# ballast register map
Vendor: tuni.fi; File version: 1.0
CPU: other r1p0, little endian, MPU, no FPU, vendor SysTick, 3 interrupt priority bits
Registers are 32-bit, read-only, no defined reset value unless marked. A register's access mark holds for its fields unless they carry their own. Offsets are from the block's base; [hi:lo] are bit positions; lines under a group give offsets from that group; {n}, {i} and the like mark numbered series; 'fields as' and 'values as' point back to an identical list.

## SYSCTRL
Base 0x20000000
0x101000 GPIO group
  0x00 PADDIR rw — Control the direction of each of the GPIO pads. A value of 1 means it is configured as an output, while 0 configures it as an input.
  0x04 PADIN rw — Input Values
  0x08 PADOUT rw — Output values.
  0x0C INTEN rw — Interrupt enable per input bit. INTTYPE0 and INTTYPE1 control the interrupt triggering behavior. There are four triggers available - INTTYPE0 = 0, INTTYPE1 = 0: Level 1 - INTTYPE0 = 1, INTTYPE1 = 0: Level 0 - INTTYPE0 = 0, INTTYPE1 = 1: Rise - INTTYPE0 = 1, INTTYPE1 = 1: Fall
  0x10 INTTYPE0 rw — Interrupt Type 0. Controls the interrupt trigger behavior together with INTTYPE1. Use INTEN to enable interrupts first.
  0x14 INTTYPE1 rw — Controls the interrupt trigger behavior together with INTTYPE0. Use INTEN to enable interrupts first.
  0x18 INTSTATUS rw — Contains interrupt status per GPIO line. The status register is cleared when read. Similarly the interrupt line is high while a bit is set in interrupt status and will be deasserted when the status register is read.
  0x1C GPIOEN rw — Contains the enable bit per GPIO line.
  {0x20+4j} PADCFG{j} rw (j=0..7) — The pad configuration registers control various aspects of the pads that are typically used in ASICs, e.g. drive strength, Schmitt-Triggers, Slew Rate, etc. Since those configuration parameters depend on the exact pads used, each implementation is free to use the PADCFG0-7 registers in every way it wants and also leave them unconnected, if unneeded. 13 Writing to the PADOUTSET address (0x1A10_1040), the content of the PADOUT register is updated with its content "ored" with the write data. Writing to the PADOUTCLR address (0x1A10_1044), the content of the PADOUT register is updated with its content "anded" with the inverted write data.
0x102000 UDMA group
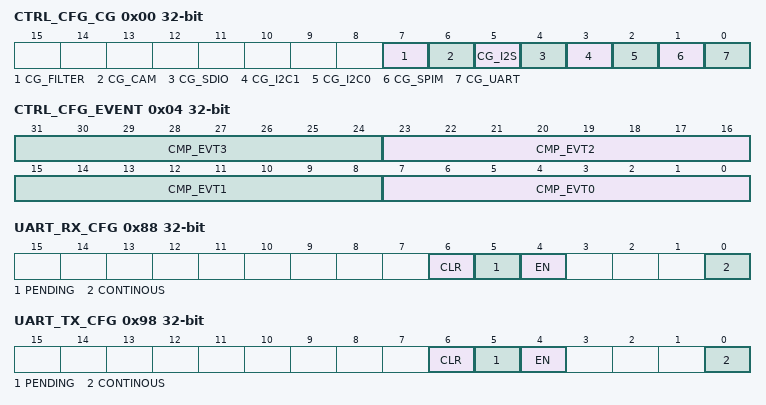
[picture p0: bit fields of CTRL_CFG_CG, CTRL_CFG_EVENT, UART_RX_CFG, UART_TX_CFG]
  0x00 CTRL_CFG_CG rw — uDMA peripherals clock gate configuration Bitfields Defines uDMA peripherals clock gate configuration for corresponding peripheral
    [7] CG_FILTER, [6] CG_CAM, [5] CG_I2S, [4] CG_SDIO, [3] CG_I2C1, [2] CG_I2C0, [1] CG_SPIM, [0] CG_UART
  0x04 CTRL_CFG_EVENT rw — uDMA peripherals external event configuration
    [8n+7:8n] CMP_EVT{n} (n=0..3) — Forward event with ID matching CMP_EVT{n} to peripherals as event{n}
  0x08 CTRL_CFG_RST rw — uDMA peripherals reset trigger (unimplemented)
  0x80 UART_RX_SADDR rw — uDMA RX UART buffer base address configuration register
    [15:0] RX_SADDR — RX buffer base address bitfield: - Read: returns value of the buffer pointer until transfer is finished. Else returns 0. - Write: sets RX buffer base address
  0x84 UART_RX_SIZE rw — uDMA RX UART buffer size configuration register
    [16:0] RX_SIZE — RX buffer size bitfield in bytes. (128kBytes maximum) - Read: returns remaining buffer size to transfer. - Write: sets buffer size.
  0x88 UART_RX_CFG rw — uDMA RX UART stream configuration register
    [6] CLR wo — RX channel clear and stop transfer: -1'b0: disable -1'b1: stop and clear the on-going transfer
    [5] PENDING ro
    [4] EN — RX channel enable and start transfer bitfield: -1'b0: disable -1'b1: enable and start the transfer This signal is used also to queue a transfer if one is already ongoing.
    [0] CONTINOUS — RX channel continuous mode bitfield: -1'b0: disabled -1'b1: enabled At the end of the buffer transfer, the uDMA reloads the address / buffer size and starts a new transfer.
  0x90 UART_TX_SADDR rw — uDMA TX UART buffer base address configuration register.
    [15:0] TX_SADDR — TX buffer base address bitfield: - Read: returns value of the buffer pointer until transfer is finished. Else returns 0. - Write: sets buffer base address
  0x94 UART_TX_SIZE rw — uDMA TX UART buffer size configuration register
    [16:0] TX_SIZE — TX buffer size bitfield in bytes. (128kBytes maximum) - Read: returns remaining buffer size to transfer. - Write: sets buffer size.
  0x98 UART_TX_CFG rw — uDMA TX UART stream configuration register.
    [6] CLR wo — RX channel clear and stop transfer: -1'b0: disable -1'b1: stop and clear the on-going transfer
    [5] PENDING ro — TX transfer pending in queue status flag: -1'b0: no pending transfer in the queue -1'b1: pending transfer in the queue
    [4] EN — TX channel enable and start transfer bitfield: -1'b0: disabled -1'b1: enable and start the transfer This signal is used also to queue a transfer if one is already ongoing.
    [0] CONTINOUS — TX channel continuous mode bitfield: -1'b0: disabled -1'b1: enabled At the end of the buffer transfer, the uDMA reloads the address / buffer size and starts a new transfer.
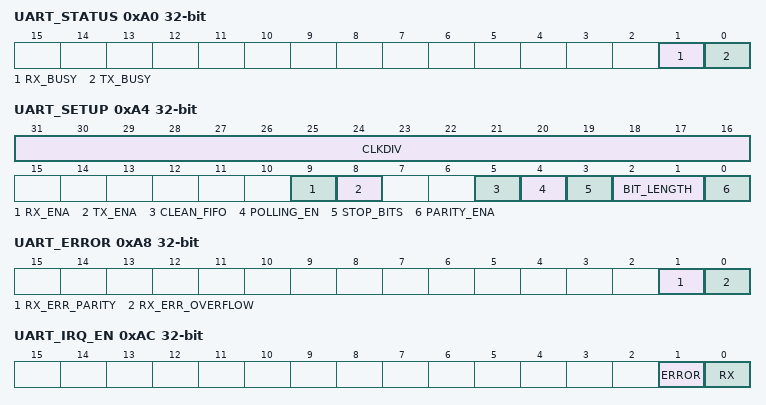
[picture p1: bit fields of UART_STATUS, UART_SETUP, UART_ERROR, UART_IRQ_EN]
  0xA0 UART_STATUS — uDMA UART status register
    [1] RX_BUSY — RX busy status flag: - 1'b0: no RX transfer on-going - 1'b1: RX transfer on-going
    [0] TX_BUSY — TX busy status flag: - 1'b0: no TX transfer on-going - 1'b1: TX transfer on-going
  0xA4 UART_SETUP rw — UDMA UART configuration register.
    [31:16] CLKDIV — UART Clock divider configuration bitfield. The baudrate is equal to SOC_FREQ/CLKDIV.
    [9] RX_ENA — RX transceiver configuration bitfield: - 1'b0: disabled - 1'b1: enabled
    [8] TX_ENA — TX transceiver configuration bitfield: - 1'b0: disabled - 1'b1: enabled
    [5] CLEAN_FIFO — In all mode clean the RX fifo, set 1 then set 0 to realize a reset fifo: - 1'b0: Stop Clean the RX FIFO. - 1'b1: Clean the RX FIFO.
    [4] POLLING_EN — When in uart read, use polling method to read the data, read interrupt enable flag will be ignored: - 1'b0: Do not using polling method to read data. - 1'b1: Using polling method to read data. Interrupt enable flag will be ignored.
    [3] STOP_BITS — Stop bits length bitfield: - 1'b0: 1 stop bit - 1'b1: 2 stop bits
    [2:1] BIT_LENGTH — Character length bitfield: - 2'b00: 5 bits - 2'b01: 6 bits - 2'b10: 7 bits - 2'b11: 8 bits
    [0] PARITY_ENA — Parity bit generation and check configuration bitfield: - 1'b0: disabled - 1'b1: enabled
  0xA8 UART_ERROR — uDMA UART Error status
    [1] RX_ERR_PARITY — RX parity error status flag: - 1'b0: no error - 1'b1: RX parity error occurred
    [0] RX_ERR_OVERFLOW — RX overflow error status flag: - 1'b0: no error - 1'b1: RX overflow error occurred
  0xAC UART_IRQ_EN rw — uDMA UART Read or Error interrupt enable register
    [1] ERROR — Error interrupt in enable flag: - 1'b0: Error IRQ disable - 1'b1: Error IRQ enable
    [0] RX — Rx interrupt in enable flag: - 1'b0: RX IRQ disable - 1'b1: RX IRQ enable
  0xB0 UART_VALID — uDMA UART Read polling data valid flag register
    [0] READY — Used only in RX polling method to indicate data is ready for read: - 1'b0: Data is not ready to read - 1'b1: Data is ready to read
  0xB4 UART_DATA — RX read data for polling or interrupt
    [7:0] BYTE
  0x100 SPIM_RX_SADDR rw — RX SPI uDMA transfer address of associated buffer
    [31:0] RX_SADDR — Configure pointer to memory buffer: - Read: value of the pointer until transfer is over. Else returns 0 - Write: set Address Pointer to memory buffer start address
  0x104 SPIM_RX_SIZE rw-once — RX SPI uDMA transfer size of buffer
    [19:0] RX_SIZE — Buffer size in bytes. (1MBytes maximum) - Read: buffer size left - Write: set buffer size
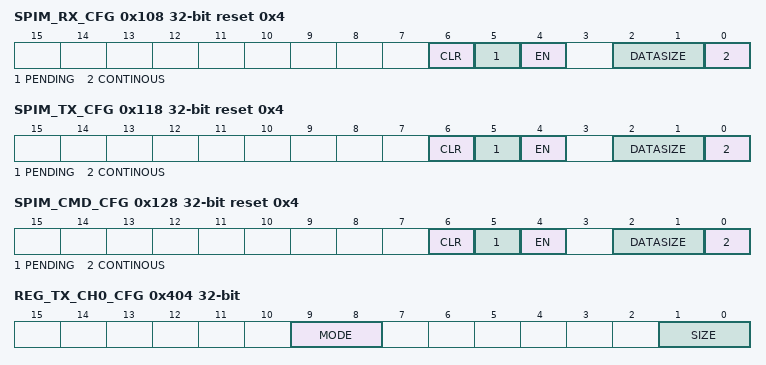
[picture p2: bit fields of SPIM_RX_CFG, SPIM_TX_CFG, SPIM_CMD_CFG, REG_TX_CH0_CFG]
  0x108 SPIM_RX_CFG rw reset 0x4 (reset mask 0x0) — RX SPI uDMA transfer configuration
    [6] CLR wo — Channel clear and stop transfer: -1'b0: disable -1'b1: enable
    [5] PENDING ro — Transfer pending in queue status flag: -1'b0: free -1'b1: pending
    [4] EN — Channel enable and start transfer: -1'b0: disable -1'b1: enable This signal is used also to queue a transfer if one is already ongoing
    [2:1] DATASIZE — Channel transfer size used to increment uDMA buffer address pointer: - 2'b00: +1 (8 bits) - 2'b01: +2 (16 bits) - 2'b10: +4 (
      0=8BITS; 1=16BITS; 2=32BITS
    [0] CONTINOUS — Channel continuous mode: -1'b0: disable -1'b1: enable At the end of the buffer the uDMA reloads the address and size and starts a new transfer.
  0x110 SPIM_TX_SADDR rw — TX SPI uDMA transfer address of associated buffer
    [31:0] TX_SADDR — Configure pointer to memory buffer: - Read: value of the pointer until transfer is over. Else returns 0 - Write: set Address Pointer to memory buffer start address
  0x114 SPIM_TX_SIZE rw — TX SPI uDMA transfer size of buffer
    [19:0] TX_SIZE — Buffer size in bytes. (1MBytes maximum) - Read: buffer size left - Write: set buffer size
  0x118 SPIM_TX_CFG rw reset 0x4 (reset mask 0x0) — TX SPI uDMA transfer configuration
    fields as UDMA.SPIM_RX_CFG
  0x120 SPIM_CMD_SADDR rw — CMD SPI uDMA transfer address of associated buffer
    [31:0] CMD_SADDR — Configure pointer to memory buffer: - Read: value of the pointer until transfer is over. Else returns 0 - Write: set Address Pointer to memory buffer start address
  0x124 SPIM_CMD_SIZE rw — CMD SPI uDMA transfer size of buffer
    [19:0] CMD_SIZE — Buffer size in bytes. (1MBytes maximum) - Read: buffer size left - Write: set buffer size
  0x128 SPIM_CMD_CFG rw reset 0x4 (reset mask 0x0) — CMD SPI uDMA transfer configuration
    fields as UDMA.SPIM_RX_CFG
  0x400 REG_TX_CH0_ADD rw — FILTER tx channel address register
  0x404 REG_TX_CH0_CFG rw — FILTER tx channel configuration register
    [9:8] MODE — Data transfer mode: - 2'b00: Linear - 2'b01: Sliding - 2;b10:Circular - 2;b11:2D
      0=LINEAR; 1=SLIDING; 2=CIRCULAR; 3=2D
    [1:0] SIZE — Data transfer format: - 2'b00: 8-bit - 2'b01:16-bit - 2;b10:32-bit
      0=8BITS; 1=16BITS; 2=32BITS
  0x408 REG_TX_CH0_LEN0 rw — FILTER tx channel length1 register
    [31:0] REG_TX_CH0_ADD
  0x40C REG_TX_CH0_LEN1 rw — FILTER tx channel length2 register
  0x410 REG_TX_CH0_LEN2 rw — FILTER tx channel 0 length2 register
  0x414 REG_TX_CH1_ADD rw — FILTER tx channel address register
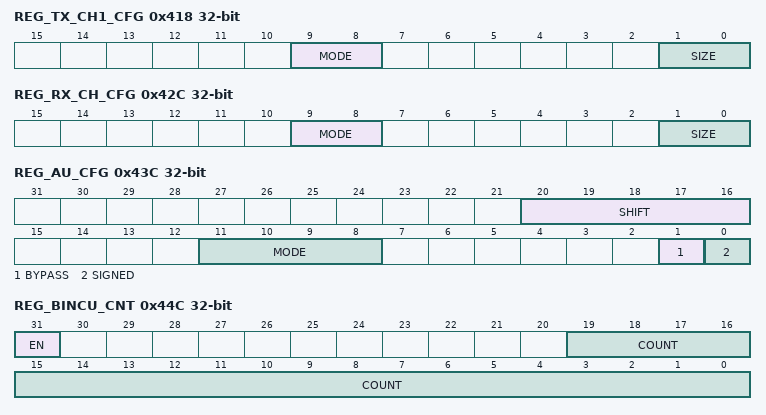
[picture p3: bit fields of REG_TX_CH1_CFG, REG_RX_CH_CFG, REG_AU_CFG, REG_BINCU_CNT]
  0x418 REG_TX_CH1_CFG rw — FILTER tx channel configuration register
    [9:8] MODE — Data transfer mode: - 2'b00: Linear - 2'b01: Sliding - 2;b10:Circular - 2;b11:2D
      1=SLIDING; 0=LINEAR; 2=CIRCULAR; 3=2D
    [1:0] SIZE — Data transfer format: - 2'b00: 8-bit - 2'b01:16-bit - 2;b10:32-bit
      0=8BITS; 1=16BITS; 2=32BITS
  0x41C REG_TX_CH1_LEN0 rw — FILTER tx channel length1 register
    [31:0] REG_TX_CH1_ADD
  0x420 REG_TX_CH1_LEN1 rw — FILTER tx channel length2 register
  0x424 REG_TX_CH1_LEN2 rw — FILTER RX channel configuration register
  0x428 REG_RX_CH_ADD rw — FILTER RX channel address register
  0x42C REG_RX_CH_CFG rw — FILTER RX channel configuration register
    fields as UDMA.REG_TX_CH1_CFG
  0x430 REG_RX_CH_LEN0 rw — FILTER RX channel configuration register
  0x434 REG_RX_CH_LEN1 rw — FILTER RX channel length1 register
  0x438 REG_RX_CH_LEN2 rw — FILTER RX channel length2 register
  0x43C REG_AU_CFG rw — FILTER arithmetic unit configuration register
    [20:16] SHIFT — Arithmetic Unit shift window size, (0 – 31).
    [11:8] MODE — Arithmetic Unit mode: -4'b0000: AU_MODE_AxB -4'b0001: AU_MODE_AxB+REG0 -4'b0010: AU_MODE_AxB accumulation -4'b0011: AU_MODE_AxA -4'b0100: AU_MODE_AxA+B -4'b0101: AU_MODE_AxA-B -4'b0110: AU_MODE_AxA accumulation -4'b0111: AU_MODE_AxA+REG0 -4'b1000: AU_MODE_AxREG1 -4'b1001: AU_MODE_AxREG1+B -4'b1010: AU_MODE_AxREG1-B -4'b1011: AU_MODE_AxREG1+REG0 -4'b1100: AU_MODE_AxREG1 accumulation -4'b1101: AU_MODE_A+B -4'b1110: AU_MODE_A-B -4'b1111: AU_MODE_A+REG0
      0=AU_MODE_AxB; 1=AU_MODE_AxBplusREG0; 2=AU_MODE_AxB_accumulation; 3=AU_MODE_AxA; 4=AU_MODE_AxAplusB; 5=AU_MODE_AxAminusB; 6=AU_MODE_AxA_accumulation; 7=AU_MODE_AxAplusREG0; 8=AU_MODE_AxREG1; 9=AU_MODE_AxREG1plusB; 10=AU_MODE_AxREG1minusB; 11=AU_MODE_AxREG1plusREG0; 12=AU_MODE_AxREG1_accumulation; 13=AU_MODE_AplusB; 14=AU_MODE_AminusB; 15=AU_MODE_AplusREG0
    [1] BYPASS — Arithmetic Unit bypass or not. -1'b0: not bypass AU -1'b1: bypass AU
    [0] SIGNED — Arithmetic Unit result signed or not. -1'b0: not signed -1'b1: signed
      0=NOT_SIGNED; 1=SIGNED
  0x440 REG_AU_REG0 rw — FILTER arithmetic unit 0 register
  0x444 REG_AU_REG1 rw — FILTER arithmetic unit 1 register
  0x448 REG_BINCU_TH rw — FILTER binarization threshold register
  0x44C REG_BINCU_CNT rw — FILTER binarization count register
    [31] EN — Binarization and counting unit enable: -1'b0: not enable -1'b1: enable
    [19:0] COUNT — Binarization and counting unit count value set.
  0x450 REG_BINCU_SETUP rw — FILTER binarization result count register
  0x454 REG_BINCU_VAL — FILTER binarization result count register
  0x458 REG_FILT rw — FILTER control mode register
  0x45C REG_FILT_CMD rw — FILTER start register
    [0] START — Filter start flag, write only, write 1 to start the filter :
  0x460 REG_STATUS rw — FILTER status register
    [0] DONE — Filter done flag, write 1 to clear the flag : -1'b0: Filter process is not finished -1'b1: Filter process is finished
0x104000 SocControl_TTA_PLL group
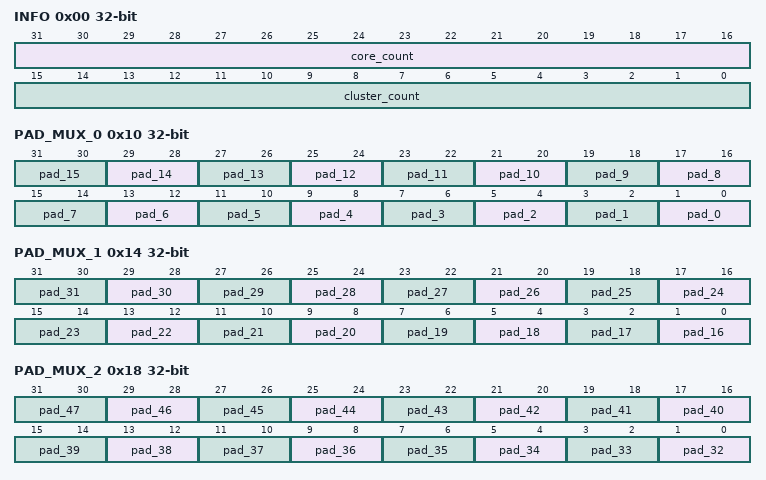
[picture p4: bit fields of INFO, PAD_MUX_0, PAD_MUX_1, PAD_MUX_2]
  0x00 INFO rw-once — This register holds the number of clusters and the number of cores in the each cluster. It is a read-only register.
    [31:16] core_count — Number of Cores
    [15:0] cluster_count — Number of Clusters
  0x04 FCBOOT rw reset 0x1A000080 (reset mask 0x0) — This register holds the boot address.
    [31:0] FCBOOT — Boot Start address
  0x08 FCFETCH wo reset 0x1 (reset mask 0x0) — This register contains the value of the fetch enable signal of the core.
    [0] FCFETCH — Enable Fetch, 1 to enable core execution
  0x10 PAD_MUX_0 rw — The content of these registers can be used to multiplex pads when targeting an ASIC. The first register (0x1A10_4010) can be used to set the mux (2 bit select) from pin 0 (bits [1:0]) to 15 (bits [31:30]).
    [2n+1:2n] pad_{n} (n=0..15)
  0x14 PAD_MUX_1 rw — The content of these registers can be used to multiplex pads when targeting an ASIC. The second register (0x1A10_4014) can be used to sets the mux (2 bit select) from pin 16 (bits [1:0]) to 31 (bits [31:30]).
    [2n-31:2n-32] pad_{n} (n=16..31)
  0x18 PAD_MUX_2 rw — The content of these registers can be used to multiplex pads when targeting an ASIC. The third register (0x1A10_4018) can be used to sets the mux (2 bit select) from pin 32 (bits [1:0]) to 47 (bits [31:30]).
    [2n-63:2n-64] pad_{n} (n=32..47)
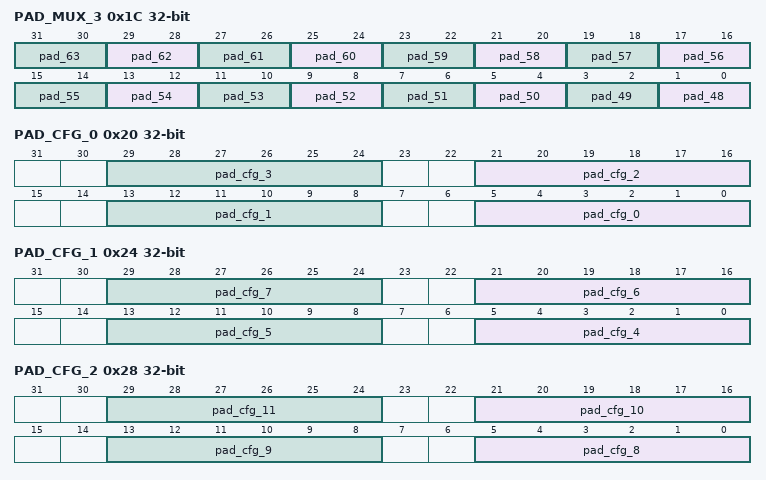
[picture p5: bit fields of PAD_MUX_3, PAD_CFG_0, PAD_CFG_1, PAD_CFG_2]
  0x1C PAD_MUX_3 rw — The content of these registers can be used to multiplex pads when targeting an ASIC. The forth register (0x1A10_401C) can be used to sets the mux (2 bit select) from pin 48 (bits [1:0]) to 63 (bits [31:30]).
    [2n-95:2n-96] pad_{n} (n=48..63)
  0x20 PAD_CFG_0 rw — 6-bits per GPIO. Pad configuration registers can be used for ASIC targets to configure pads, e.g. pull up, pull down values.
    [8n+5:8n] pad_cfg_{n} (n=0..3)
  0x24 PAD_CFG_1 rw — Pad configuration registers can be used for ASIC targets to configure pads, e.g. pull up, pull down values.
    [8n-27:8n-32] pad_cfg_{n} (n=4..7)
  0x28 PAD_CFG_2 rw — Pad configuration registers can be used for ASIC targets to configure pads, e.g. pull up, pull down values.
    [8n-59:8n-64] pad_cfg_{n} (n=8..11)
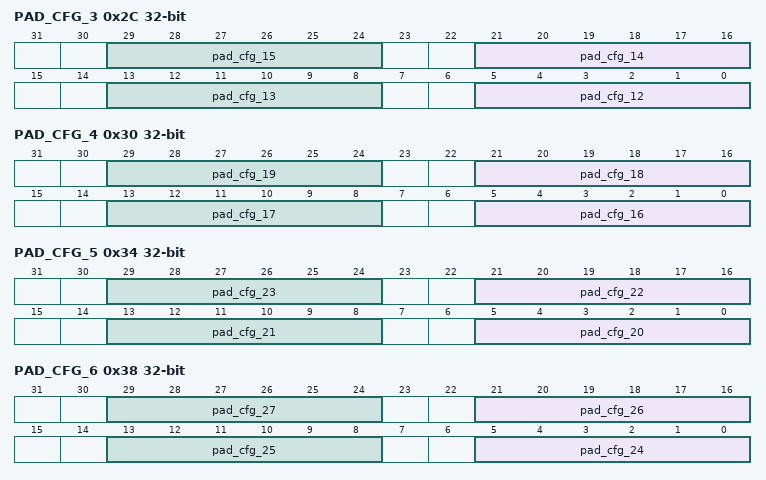
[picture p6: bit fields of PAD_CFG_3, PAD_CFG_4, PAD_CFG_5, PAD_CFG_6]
  0x2C PAD_CFG_3 rw — Pad configuration registers can be used for ASIC targets to configure pads, e.g. pull up, pull down values.
    [8n-91:8n-96] pad_cfg_{n} (n=12..15)
  0x30 PAD_CFG_4 rw — Pad configuration registers can be used for ASIC targets to configure pads, e.g. pull up, pull down values.
    [8n-123:8n-128] pad_cfg_{n} (n=16..19)
  0x34 PAD_CFG_5 rw — Pad configuration registers can be used for ASIC targets to configure pads, e.g. pull up, pull down values.
    [8n-155:8n-160] pad_cfg_{n} (n=20..23)
  0x38 PAD_CFG_6 rw — Pad configuration registers can be used for ASIC targets to configure pads, e.g. pull up, pull down values.
    [8n-187:8n-192] pad_cfg_{n} (n=24..27)
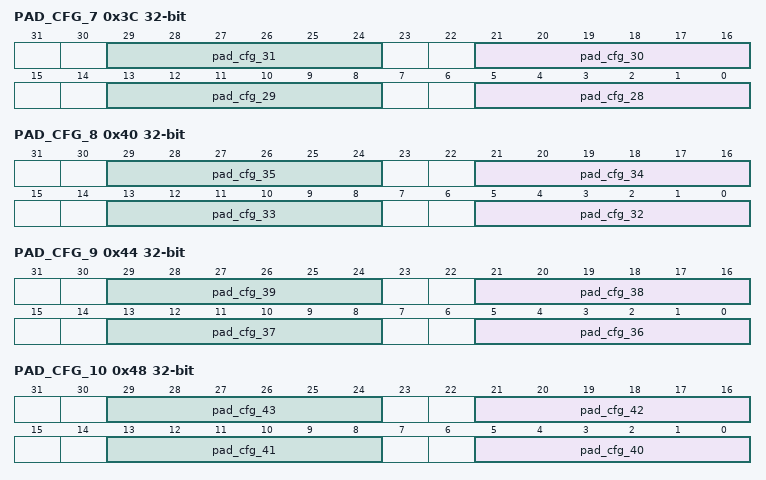
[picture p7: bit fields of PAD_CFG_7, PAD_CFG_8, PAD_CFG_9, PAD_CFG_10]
  0x3C PAD_CFG_7 rw — Pad configuration registers can be used for ASIC targets to configure pads, e.g. pull up, pull down values.
    [8n-219:8n-224] pad_cfg_{n} (n=28..31)
  0x40 PAD_CFG_8 rw — Pad configuration registers can be used for ASIC targets to configure pads, e.g. pull up, pull down values.
    [8n-251:8n-256] pad_cfg_{n} (n=32..35)
  0x44 PAD_CFG_9 rw — Pad configuration registers can be used for ASIC targets to configure pads, e.g. pull up, pull down values.
    [8n-283:8n-288] pad_cfg_{n} (n=36..39)
  0x48 PAD_CFG_10 rw — Pad configuration registers can be used for ASIC targets to configure pads, e.g. pull up, pull down values.
    [8n-315:8n-320] pad_cfg_{n} (n=40..43)
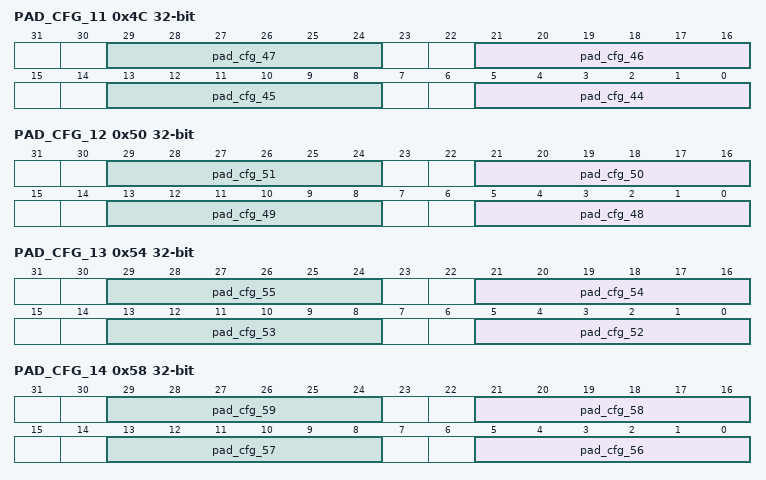
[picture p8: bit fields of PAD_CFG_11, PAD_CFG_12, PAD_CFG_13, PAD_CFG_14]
  0x4C PAD_CFG_11 rw — Pad configuration registers can be used for ASIC targets to configure pads, e.g. pull up, pull down values.
    [8n-347:8n-352] pad_cfg_{n} (n=44..47)
  0x50 PAD_CFG_12 rw — Pad configuration registers can be used for ASIC targets to configure pads, e.g. pull up, pull down values.
    [8n-379:8n-384] pad_cfg_{n} (n=48..51)
  0x54 PAD_CFG_13 rw — Pad configuration registers can be used for ASIC targets to configure pads, e.g. pull up, pull down values.
    [8n-411:8n-416] pad_cfg_{n} (n=52..55)
  0x58 PAD_CFG_14 rw — Pad configuration registers can be used for ASIC targets to configure pads, e.g. pull up, pull down values.
    [8n-443:8n-448] pad_cfg_{n} (n=56..59)
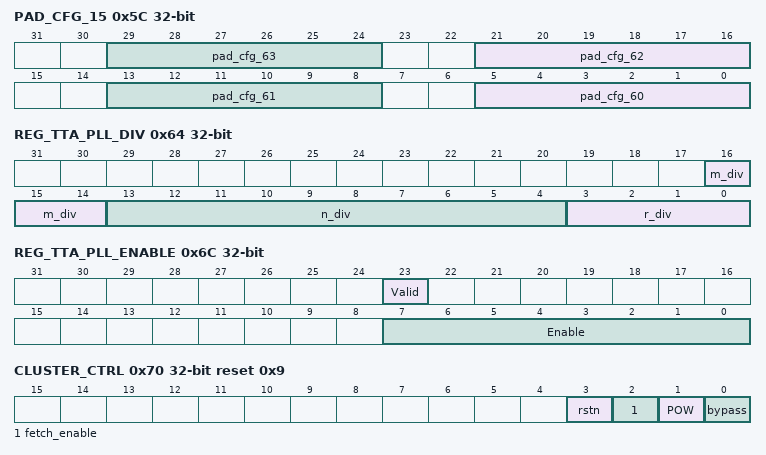
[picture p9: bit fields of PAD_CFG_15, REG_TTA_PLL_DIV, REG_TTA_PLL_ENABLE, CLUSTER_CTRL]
  0x5C PAD_CFG_15 rw — Pad configuration registers can be used for ASIC targets to configure pads, e.g. pull up, pull down values.
    [8n-475:8n-480] pad_cfg_{n} (n=60..63)
  0x60 REG_TTA_PLL_LOOP_CTRL rw
    [31:0] LOOP_CTRL
  0x64 REG_TTA_PLL_DIV rw
    [16:14] m_div, [13:4] n_div, [3:0] r_div
  0x68 REG_TTA_PLL_DEBUG_CTRL rw
    [7:0] Debug_Ctrl
  0x6C REG_TTA_PLL_ENABLE rw
    [23] Valid, [7:0] Enable
  0x70 CLUSTER_CTRL rw reset 0x9 (reset mask 0x0)
    [3] rstn, [2] fetch_enable, [1] POW, [0] bypass
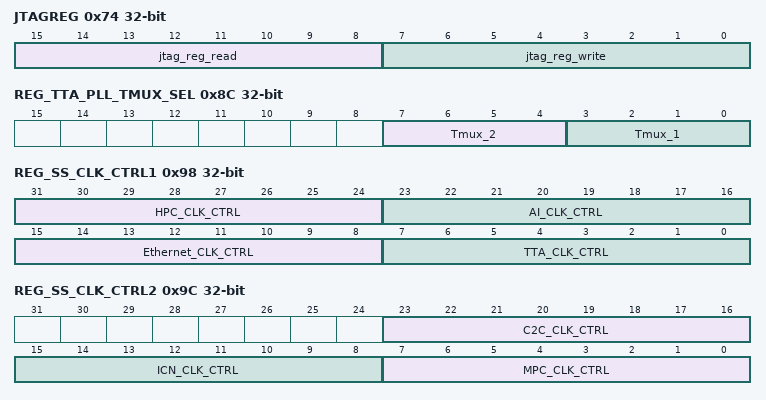
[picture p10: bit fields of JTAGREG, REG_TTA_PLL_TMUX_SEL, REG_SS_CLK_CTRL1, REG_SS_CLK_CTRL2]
  0x74 JTAGREG rw — Register to read or write from JTAG
    [15:8] jtag_reg_read, [7:0] jtag_reg_write
  0x78 CTRL_PER rw
    [0] Sel_hyper_axi
  0x7C CLUSTER_IRQ rw
    [0] Cluster_IRQ
  0x80 CLUSTER_BOOT_ADDR0 rw
  0x84 CLUSTER_BOOT_ADDR1 rw
  0x88 REG_TTA_PLL_SPARE_CTRL rw
    [31:0] spare_ctrl
  0x8C REG_TTA_PLL_TMUX_SEL rw
    [7:4] Tmux_2, [3:0] Tmux_1
  0x90 REG_TTA_PLL_STATUS1
  0x94 REG_TOPPERIPH_CLK_DIV rw
    [15:0] REG_TOPPERIPH_CLK_DIV — Clock divider ratio for Top peripheral module
  0x98 REG_SS_CLK_CTRL1 rw — Subsystem Clock selection. Bit definition *_CLK_CTRL Bitfield definitions [bit]:[field] 0: sel_cka 1: force_cka 2: force_ckb 3: subsys_clkena 4: - 5: - 6: - 7: pll_ctrl_valid
    [31:24] HPC_CLK_CTRL, [23:16] AI_CLK_CTRL, [15:8] Ethernet_CLK_CTRL, [7:0] TTA_CLK_CTRL
  0x9C REG_SS_CLK_CTRL2 rw — Subsystem Clock selection. Bit definition *_CLK_CTRL Bitfield definitions [bit]:[field] 0: sel_cka 1: force_cka 2: force_ckb 3: subsys_clkena 4: - 5: - 6: - 7: pll_ctrl_valid
    [23:16] C2C_CLK_CTRL, [15:8] ICN_CLK_CTRL, [7:0] MPC_CLK_CTRL
  0xA0 CORESTATUS rw — These 2 registers (CORESTATUS, CS_RO) contain the status of the system for testing/verification purposes like End Of Computation. The 0x1A10_40C0 register is read-only.
    [1:0] CORE_STATUS
  0xA4 REG_SLOW_PULSE_DIV rw
    [9:0] SLOW_PULSE_DIV
  0xA8 REG_PERIPH_CLK_DIV rw
    [9:0] PERIPH_CLK_DIV
  0xB0 REG_SS_RESET_EN rw — Assertion of the Subsystem bit, deasserts the reset to the corresponding subsystem. Bit definition is mentioned in adjoining table SS Clock and Reset Enable layout: 0: Pulpissimo 4: interconnect 7: Top peripheral 8: c2c 12: CoreHW 16: TTA 20: Ethernet 24: AI 28: HPC Other bits unused
  0xB4 REG_SS_CLK_EN rw — SS Clock and Reset Enable layout: 0: Pulpissimo 4: interconnect 7: Top peripheral 8: c2c 12: CoreHW 16: TTA 20: Ethernet 24: AI 28: HPC Other bits unused
    [31:0] REG_SS_CLK_EN — Assertion of the Subsystem bit, Enables clock to the corresponding subsystem. Bit definition is mentioned in adjoining table
  0xB8 REG_SS_CLK_CTRL3 rw — Subsystem Clock selection. Bit definition *_CLK_CTRL Bitfield definitions [bit]:[field] 0: sel_cka 1: force_cka 2: force_ckb 3: subsys_clkena 4: - 5: - 6: - 7: pll_ctrl_valid
    [7:0] Top_Periph_CLK_CTRL
  0xBC REG_TTA_PLL_STATUS2
  0xC0 CS_RO
  0xC4 BOOTSEL — Boot Sel value
    [31:0] bootsel_pad
  0xC8 CLKSEL
    [31:0] CLKSEL — Irrelevant. Select FLL clock. Sysctrl does not have FLL
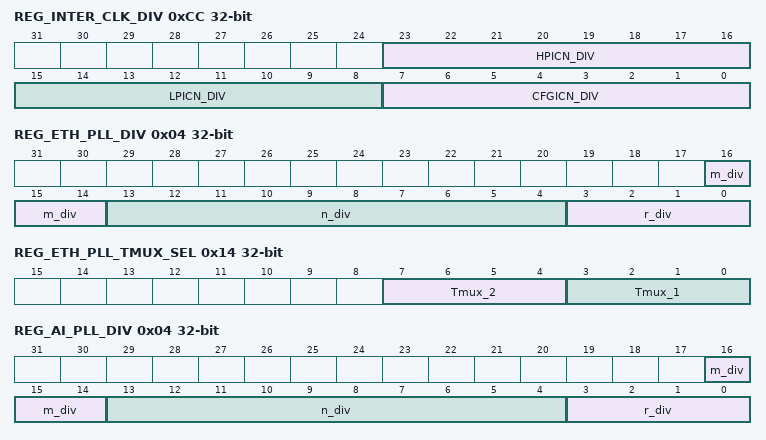
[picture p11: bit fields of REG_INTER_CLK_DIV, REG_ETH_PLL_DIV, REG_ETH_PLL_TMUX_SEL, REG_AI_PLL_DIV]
  0xCC REG_INTER_CLK_DIV rw — Clock divider ratio for the 3 Interconnect modules
    [23:16] HPICN_DIV, [15:8] LPICN_DIV, [7:0] CFGICN_DIV
0x1040D0 ETH_PLL group
  0x00 REG_ETH_PLL_LOOP_CTRL rw
    [31:0] LOOP_CTRL
  0x04 REG_ETH_PLL_DIV rw
    [16:14] m_div, [13:4] n_div, [3:0] r_div
  0x08 REG_ETH_PLL_DEBUG_CTRL rw
    [7:0] Debug_Ctrl
  0x0C REG_ETH_PLL_ENABLE rw
    [31:0] spare_ctrl
  0x10 REG_ETH_PLL_SPARE_CTRL rw
    [31:0] spare_ctrl
  0x14 REG_ETH_PLL_TMUX_SEL rw
    [7:4] Tmux_2, [3:0] Tmux_1
  0x18 REG_ETH_PLL_STATUS1
  0x1C REG_ETH_PLL_STATUS2
0x1040F0 AI_PLL group
  0x00 REG_AI_PLL_LOOP_CTRL rw
    [31:0] LOOP_CTRL
  0x04 REG_AI_PLL_DIV rw
    [16:14] m_div, [13:4] n_div, [3:0] r_div
  0x08 REG_AI_PLL_DEBUG_CTRL rw
    [7:0] Debug_Ctrl
  0x0C REG_AI_PLL_ENABLE rw
    [31:0] spare_ctrl
  0x10 REG_AI_PLL_SPARE_CTRL rw
    [31:0] spare_ctrl
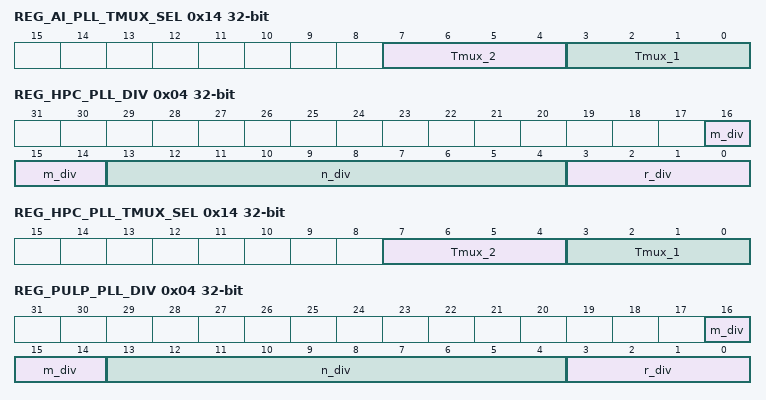
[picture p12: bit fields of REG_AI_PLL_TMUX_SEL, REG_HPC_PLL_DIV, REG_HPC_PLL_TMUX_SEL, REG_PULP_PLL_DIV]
  0x14 REG_AI_PLL_TMUX_SEL rw
    [7:4] Tmux_2, [3:0] Tmux_1
  0x18 REG_AI_PLL_STATUS1
  0x1C REG_AI_PLL_STATUS2
0x104110 HPC_PLL group
  0x00 REG_HPC_PLL_LOOP_CTRL rw
    [31:0] LOOP_CTRL
  0x04 REG_HPC_PLL_DIV rw
    [16:14] m_div, [13:4] n_div, [3:0] r_div
  0x08 REG_HPC_PLL_DEBUG_CTRL rw
    [7:0] Debug_Ctrl
  0x0C REG_HPC_PLL_ENABLE rw
    [31:0] spare_ctrl
  0x10 REG_HPC_PLL_SPARE_CTRL rw
    [31:0] spare_ctrl
  0x14 REG_HPC_PLL_TMUX_SEL rw
    [7:4] Tmux_2, [3:0] Tmux_1
  0x18 REG_HPC_PLL_STATUS1
  0x1C REG_HPC_PLL_STATUS2
0x104130 PULP_PLL group
  0x00 REG_PULP_PLL_LOOP_CTRL rw
    [31:0] LOOP_CTRL
  0x04 REG_PULP_PLL_DIV rw
    [16:14] m_div, [13:4] n_div, [3:0] r_div
  0x08 REG_PULP_PLL_DEBUG_CTRL rw
    [7:0] Debug_Ctrl
  0x0C REG_PULP_PLL_ENABLE rw
    [31:0] spare_ctrl
  0x10 REG_PULP_PLL_SPARE_CTRL rw
    [31:0] spare_ctrl
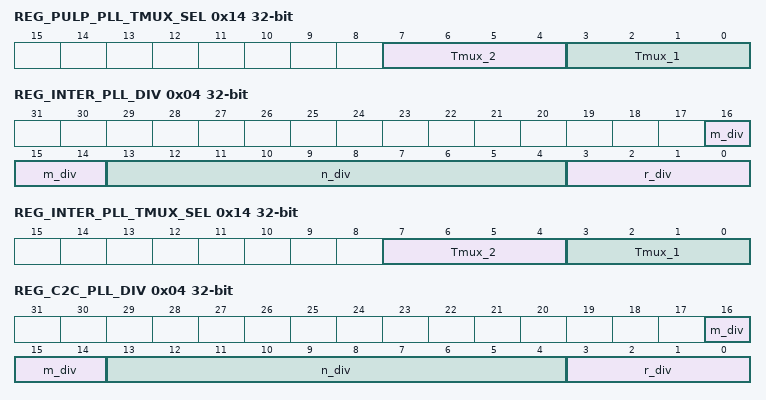
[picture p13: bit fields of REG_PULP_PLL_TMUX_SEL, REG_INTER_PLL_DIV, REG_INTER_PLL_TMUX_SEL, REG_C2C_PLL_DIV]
  0x14 REG_PULP_PLL_TMUX_SEL rw
    [7:4] Tmux_2, [3:0] Tmux_1
  0x18 REG_PULP_PLL_STATUS1
  0x1C REG_PULP_PLL_STATUS2
0x104150 INTER_PLL group
  0x00 REG_INTER_PLL_LOOP_CTRL rw
    [31:0] LOOP_CTRL
  0x04 REG_INTER_PLL_DIV rw
    [16:14] m_div, [13:4] n_div, [3:0] r_div
  0x08 REG_INTER_PLL_DEBUG_CTRL rw
    [7:0] Debug_Ctrl
  0x0C REG_INTER_PLL_ENABLE rw
    [31:0] spare_ctrl
  0x10 REG_INTER_PLL_SPARE_CTRL rw
    [31:0] spare_ctrl
  0x14 REG_INTER_PLL_TMUX_SEL rw
    [7:4] Tmux_2, [3:0] Tmux_1
  0x18 REG_INTER_PLL_STATUS1
  0x1C REG_INTER_PLL_STATUS2
0x104170 C2C_PLL group
  0x00 REG_C2C_PLL_LOOP_CTRL rw
    [31:0] LOOP_CTRL
  0x04 REG_C2C_PLL_DIV rw
    [16:14] m_div, [13:4] n_div, [3:0] r_div
  0x08 REG_C2C_PLL_DEBUG_CTRL rw
    [7:0] Debug_Ctrl
  0x0C REG_C2C_PLL_ENABLE rw
    [31:0] spare_ctrl
  0x10 REG_C2C_PLL_SPARE_CTRL rw
    [31:0] spare_ctrl
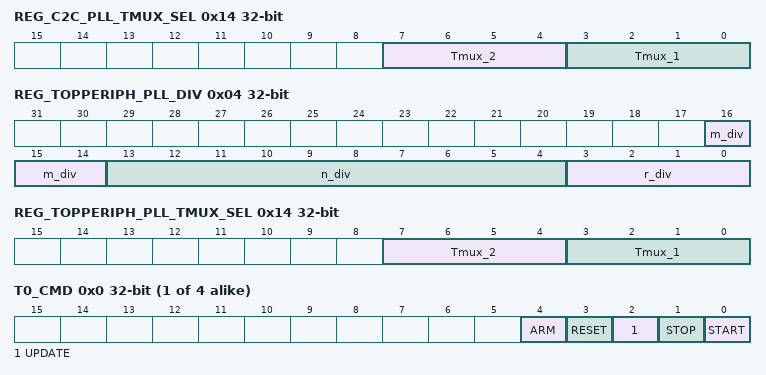
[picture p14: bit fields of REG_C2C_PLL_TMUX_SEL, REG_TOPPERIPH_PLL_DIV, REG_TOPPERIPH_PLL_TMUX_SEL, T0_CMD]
  0x14 REG_C2C_PLL_TMUX_SEL rw
    [7:4] Tmux_2, [3:0] Tmux_1
  0x18 REG_C2C_PLL_STATUS1
  0x1C REG_C2C_PLL_STATUS2
0x1041B0 TOPPERIPH_PLL group
  0x00 REG_TOPPERIPH_PLL_LOOP_CTRL rw
    [31:0] LOOP_CTRL
  0x04 REG_TOPPERIPH_PLL_DIV rw
    [16:14] m_div, [13:4] n_div, [3:0] r_div
  0x08 REG_TOPPERIPH_PLL_DEBUG_CTRL rw
    [7:0] Debug_Ctrl
  0x0C REG_TOPPERIPH_PLL_ENABLE rw
    [31:0] spare_ctrl
  0x10 REG_TOPPERIPH_PLL_SPARE_CTRL rw
    [31:0] spare_ctrl
  0x14 REG_TOPPERIPH_PLL_TMUX_SEL rw
    [7:4] Tmux_2, [3:0] Tmux_1
  0x18 REG_TOPPERIPH_PLL_STATUS1
  0x1C REG_TOPPERIPH_PLL_STATUS2
0x1041D0 BootConfig group
  0x00 REG_BOOT_CFG rw
  0x04 REG_BOOT_STATUS rw
0x105000 AdvancedTimer group
  {0x0+0x40*j} T{j}_CMD rw (j=0..3) — ADV_TIMER{j} command register
    [4] ARM — ADV_TIMER{j} arm command bitfield.
    [3] RESET — ADV_TIMER{j} reset command bitfield
    [2] UPDATE — ADV_TIMER{j} update command bitfield.
    [1] STOP — ADV_TIMER{j} stop command bitfield.
    [0] START — ADV_TIMER{j} start command bitfield
  0x04 T0_CONFIG rw — ADV_TIMER0 configuration register.
    [23:16] PRESC — ADV_TIMER0 prescaler value configuration bitfield.
    [12] UPDOWNSEL — ADV_TIMER0 center-aligned mode configuration bitfield: - 1'b0: The counter counts up and down alternatively. - 1'b1: The counter counts up and resets to 0 when reach threshold.
    [11] CLKSEL — ADV_TIMER0 clock source configuration bitfield: - 1'b0: FLL - 1'b1: reference clock at 32kHz
    [10:8] MODE — ADV_TIMER0 trigger mode configuration bitfield: - 3'h0: trigger event at each clock cycle. - 3'h1: trigger event if input source is 0 - 3'h2: trigger event if input source is 1 - 3'h3: trigger event on input source rising edge - 3'h4: trigger event on input source falling edge - 3'h5: trigger event on input source falling or rising edge - 3'h6: trigger event on input source rising edge when armed - 3'h7: trigger event on input source falling edge when armed
    [7:0] INSEL — ADV_TIMER0 input source configuration bitfield: - 0-31: GPIO[0] to GPIO[31] - 32-35: Channel 0 to 3 of ADV_TIMER0 - 36-39: Channel 0 to 3 of ADV_TIMER1 - 40-43: Channel 0 to 3 of ADV_TIMER2 - 44-47: Channel 0 to 3 of ADV_TIMER3
  0x08 T0_THRESHOLD rw — ADV_TIMER0 threshold configuration register.
    [31:16] TH_HI — ADV_TIMER0 threshold high part configuration bitfield. It defines end counter value.
    [15:0] TH_LO — ADV_TIMER0 threshold low part configuration bitfield. It defines start counter value
  0x0C T0_TH_CHANNEL0 rw — ADV_TIMER0 channel 0 threshold configuration register
    [18:16] MODE — ADV_TIMER0 channel 0 threshold match action on channel output signal configuration bitfield: - 3'h0: set. - 3'h1: toggle then next threshold match action is clear. - 3'h2: set then next threshold match action is clear. - 3'h3: toggle. - 3'h4: clear. - 3'h5: toggle then next threshold match action is set. - 3'h6: clear then next threshold match action is set.
      0=SET; 1=TOGGLE_CLEAR_NEXT; 2=SET_CLEAR_NEXT; 3=TOGGLE; 4=CLEAR; 5=TOGGLE_SET_NEXT; 6=CLEAR_SET_NEXT
    [15:0] TH — ADV_TIMER0 channel 0 threshold configuration bitfield
  {0xC+4j} T0_TH_CHANNEL{j} rw (j=1..3) — ADV_TIMER0 channel {j} threshold configuration register
    [18:16] MODE — ADV_TIMER0 channel {j} threshold match action on channel output signal configuration bitfield: - 3'h0: set. - 3'h1: toggle then next threshold match action is clear. - 3'h2: set then next threshold match action is clear. - 3'h3: toggle. - 3'h4: clear. - 3'h5: toggle then next threshold match action is set. - 3'h6: clear then next threshold match action is set.
      5=TOGGLE_SET_NEXT; 1=TOGGLE_CLEAR_NEXT; 3=TOGGLE; 2=SET_CLEAR_NEXT; 0=SET; 6=CLEAR_SET_NEXT; 4=CLEAR
    [15:0] TH — ADV_TIMER0 channel {j} threshold configuration bitfield
  0x2C T0_COUNTER — ADV_TIMER0 counter register
  {0x4+0x40*j} T{j}_CONFIG rw (j=1..3) — ADV_TIMER{j} configuration register
    [23:16] PRESC — ADV_TIMER{j} prescaler value configuration bitfield.
    [12] UPDOWNSEL — ADV_TIMER{j} center-aligned mode configuration bitfield: - 1'b0: The counter counts up and down alternatively. - 1'b1: The counter counts up and resets to 0 when reach threshold.
    [11] CLKSEL — ADV_TIMER{j} clock source configuration bitfield: - 1'b0: FLL - 1'b1: reference clock at 32kHz
    [10:8] MODE — ADV_TIMER{j} trigger mode configuration bitfield: - 3'h0: trigger event at each clock cycle. - 3'h1: trigger event if input source is 0 - 3'h2: trigger event if input source is 1 - 3'h3: trigger event on input source rising edge - 3'h4: trigger event on input source falling edge - 3'h5: trigger event on input source falling or rising edge - 3'h6: trigger event on input source rising edge when armed - 3'h7: trigger event on input source falling edge when armed
    [7:0] INSEL — ADV_TIMER{j} input source configuration bitfield: - 0-31: GPIO[0] to GPIO[31] - 32-35: Channel 0 to 3 of ADV_TIMER0 - 36-39: Channel 0 to 3 of ADV_TIMER1 - 40-43: Channel 0 to 3 of ADV_TIMER2 - 44-47: Channel 0 to 3 of ADV_TIMER3
  {0x8+0x40*j} T{j}_THRESHOLD rw (j=1..3) — ADV_TIMER{j} threshold configuration register
    [31:16] TH_HI — ADV_TIMER{j} threshold high part configuration bitfield. It defines end counter value.
    [15:0] TH_LO — ADV_TIMER{j} threshold low part configuration bitfield. It defines start counter value
  0x4C T1_TH_CHANNEL0 rw — ADV_TIMER1 channel 0 threshold configuration register
    [18:16] MODE — ADV_TIMER1 channel 0 threshold match action on channel output signal configuration bitfield: - 3'h0: set. - 3'h1: toggle then next threshold match action is clear. - 3'h2: set then next threshold match action is clear. - 3'h3: toggle. - 3'h4: clear. - 3'h5: toggle then next threshold match action is set. - 3'h6: clear then next threshold match action is set.
      values as AdvancedTimer.T0_TH_CHANNEL1.MODE
    [15:0] TH — ADV_TIMER1 channel 0 threshold configuration bitfield
  0x50 T1_TH_CHANNEL1 rw — ADV_TIMER1 channel 1 threshold configuration register
    [18:16] MODE — ADV_TIMER1 channel 1 threshold match action on channel output signal configuration bitfield: - 3'h0: set. - 3'h1: toggle then next threshold match action is clear. - 3'h2: set then next threshold match action is clear. - 3'h3: toggle. - 3'h4: clear. - 3'h5: toggle then next threshold match action is set. - 3'h6: clear then next threshold match action is set.
      2=SET_CLEAR_NEXT; 4=CLEAR; 0=SET; 5=TOGGLE_SET_NEXT; 6=CLEAR_SET_NEXT; 1=TOGGLE_CLEAR_NEXT; 3=TOGGLE
    [15:0] TH — ADV_TIMER1 channel 1 threshold configuration bitfield
  0x54 T1_TH_CHANNEL2 rw — ADV_TIMER1 channel 2 threshold configuration register
    [18:16] MODE — ADV_TIMER2 channel 1 threshold match action on channel output signal configuration bitfield: - 3'h0: set. - 3'h1: toggle then next threshold match action is clear. - 3'h2: set then next threshold match action is clear. - 3'h3: toggle. - 3'h4: clear. - 3'h5: toggle then next threshold match action is set. - 3'h6: clear then next threshold match action is set.
      values as AdvancedTimer.T0_TH_CHANNEL1.MODE
    [15:0] TH — ADV_TIMER2 channel 1 threshold configuration bitfield
  0x58 T1_TH_CHANNEL3 rw — ADV_TIMER1 channel 3 threshold configuration register
    [18:16] MODE — ADV_TIMER1 channel 3 threshold match action on channel output signal configuration bitfield: - 3'h0: set. - 3'h1: toggle then next threshold match action is clear. - 3'h2: set then next threshold match action is clear. - 3'h3: toggle. - 3'h4: clear. - 3'h5: toggle then next threshold match action is set. - 3'h6: clear then next threshold match action is set.
      values as AdvancedTimer.T0_TH_CHANNEL1.MODE
    [15:0] TH — ADV_TIMER1 channel 3 threshold configuration bitfield
  0x6C T1_COUNTER — ADV_TIMER1 counter register
  {0x8C+4j} T2_TH_CHANNEL{j} rw (j=0..3) — ADV_TIMER2 channel {j} threshold configuration register
    [18:16] MODE — ADV_TIMER2 channel {j} threshold match action on channel output signal configuration bitfield: - 3'h0: set. - 3'h1: toggle then next threshold match action is clear. - 3'h2: set then next threshold match action is clear. - 3'h3: toggle. - 3'h4: clear. - 3'h5: toggle then next threshold match action is set. - 3'h6: clear then next threshold match action is set.
      values as AdvancedTimer.T0_TH_CHANNEL1.MODE
    [15:0] TH — ADV_TIMER2 channel {j} threshold configuration bitfield
  0xAC T2_COUNTER rw — ADV_TIMER2 counter register
  {0xCC+4j} T3_TH_CHANNEL{j} rw (j=0..3) — ADV_TIMER3 channel {j} threshold configuration register
    [18:16] MODE — ADV_TIMER3 channel {j} threshold match action on channel output signal configuration bitfield: - 3'h0: set. - 3'h1: toggle then next threshold match action is clear. - 3'h2: set then next threshold match action is clear. - 3'h3: toggle. - 3'h4: clear. - 3'h5: toggle then next threshold match action is set. - 3'h6: clear then next threshold match action is set.
      values as AdvancedTimer.T0_TH_CHANNEL1.MODE
    [15:0] TH — ADV_TIMER3 channel {j} threshold configuration bitfield
  0xEC T3_COUNTER — ADV_TIMER3 counter register
  0x100 EVENT_CFG rw — ADV_TIMERS events configuration register.
  0x104 CG rw — ADV_TIMERS channels clock gating configuration register.
    [15:0] ENA — ADV_TIMER clock gating configuration bitfield. - ENA[i]=0: clock gate ADV_TIMERi. - ENA[i]=1: enable ADV_TIMERi.
0x106000 SocEventGenerator group
  0x00 SW_EVENT wo — SoC software events trigger register
    [7:0] EVENT — Writing a one-hot value into EVENT triggers a SoC software event. 8 software events are available.
  {0x4+4j} FC_MASK{j} rw reset 0xFFFFFFFF (reset mask 0x0) (j=0..5) — Events {32j}-{32j+31} dispatch mask to FC
    [31:0] FC_MASK{j} — Event Mask to enable/disable event dispatch to FC interrupt controller. Setting bit[i] to 0b1 disables dispatching event to FC interrupt controller. Setting bit[i] to 0b0 enables dispatching event to FC interrupt controller.
  0x1C FC_MASK6 rw reset 0xFFFFFFFF (reset mask 0x0) — Events 191-223 dispatch mask to FC
    [31:0] FC_MASK6 — Event Mask to enable/disable event dispatch to FC interrupt controller. Setting bit[i] to 0b1 disables dispatching event to FC interrupt controller. Setting bit[i] to 0b0 enables dispatching event to FC interrupt controller.
  0x20 FC_MASK7 rw reset 0xFFFFFFFF (reset mask 0x0) — F Events 224-255 dispatch mask to peripherals
    [31:0] FC_MASK7 — Event Mask to enable/disable event dispatch to FC interrupt controller. Setting bit[i] to 0b1 disables dispatching event to FC interrupt controller. Setting bit[i] to 0b0 enables dispatching event to FC interrupt controller.
  0x44 PR_MASK0 rw reset 0xFFFFFFFF (reset mask 0x0) — Events 0-31 dispatch mask to peripherals
  0x48 PR_MASK1 rw reset 0xFFFFFFFF (reset mask 0x0)
    [31:0] PR_MASK1 — Event Mask to enable/disable event dispatch to peripherals. Setting bit[i] to 0b1 disables dispatching event to peripherals. Setting bit[i] to 0b0 enables dispatching event to peripherals.
  0x4C PR_MASK2 rw reset 0xFFFFFFFF (reset mask 0x0) — Events 0-31 dispatch mask to peripheralsEvents 64-95 dispatch mask to peripherals
    [31:0] PR_MASK2 — Event Mask to enable/disable event dispatch to peripherals. Setting bit[i] to 0b1 disables dispatching event to peripherals. Setting bit[i] to 0b0 enables dispatching event to peripherals.
  0x50 PR_MASK3 rw reset 0xFFFFFFFF (reset mask 0x0) — Events 96-127 dispatch mask to peripherals
    [31:0] PR_MASK3 — Event Mask to enable/disable event dispatch to peripherals. Setting bit[i] to 0b1 disables dispatching event to peripherals. Setting bit[i] to 0b0 enables dispatching event to peripherals.
  0x54 PR_MASK4 rw reset 0xFFFFFFFF (reset mask 0x0) — Events 128-159 dispatch mask to peripheral
    [31:0] PR_MASK4 — Event Mask to enable/disable event dispatch to peripherals. Setting bit[i] to 0b1 disables dispatching event to peripherals. Setting bit[i] to 0b0 enables dispatching event to peripherals.
  0x58 PR_MASK5 rw reset 0xFFFFFFFF (reset mask 0x0) — Events 160-191 dispatch mask to peripherals
    [31:0] PR_MASK5 — Event Mask to enable/disable event dispatch to peripherals. Setting bit[i] to 0b1 disables dispatching event to peripherals. Setting bit[i] to 0b0 enables dispatching event to peripherals.
  0x5C PR_MASK6 rw reset 0xFFFFFFFF (reset mask 0x0) — Events 191-223 dispatch mask to peripherals
    [31:0] PR_MASK6 — Event Mask to enable/disable event dispatch to peripherals. Setting bit[i] to 0b1 disables dispatching event to peripherals. Setting bit[i] to 0b0 enables dispatching event to peripherals.
  0x60 PR_MASK7 rw reset 0xFFFFFFFF (reset mask 0x0) — Events 224-255 dispatch mask to peripherals
    [31:0] PR_MASK7 — Event Mask to enable/disable event dispatch to peripherals. Setting bit[i] to 0b1 disables dispatching event to peripherals. Setting bit[i] to 0b0 enables dispatching event to peripherals.
  0x64 ERR0 — Events 0-31 event queue overflow
    [31:0] ERR0 — Event queue overflow. Clear after read. Reading 0b1 at ERR[i] means the event queue of event with id i overflowed.
  0x68 ERR1 — Events 32-63 event queue overflow
    [31:0] ERR1 — Event queue overflow. Clear after read. Reading 0b1 at ERR[i] means the event queue of event with id i overflowed.
  0x6C ERR2 — Events 64-95 event queue overflow
    [31:0] ERR02 — Event queue overflow. Clear after read. Reading 0b1 at ERR[i] means the event queue of event with id i overflowed.
  {0x64+4j} ERR{j} (j=3..5) — Events {32j}-{32j+31} event queue overflow
    [31:0] ERR{j} — Event queue overflow. Clear after read. Reading 0b1 at ERR[i] means the event queue of event with id i overflowed.
  0x7C ERR6 — Events 191-223 event queue overflow
    [31:0] ERR6 — Event queue overflow. Clear after read. Reading 0b1 at ERR[i] means the event queue of event with id i overflowed.
  0x80 ERR7 — Events 224-255 event queue overflow
  0x84 TIMER_LO access not given
    [7:0] TIMER_LO_EVENT — Trigger and start APB Timer LO by the event with id that equals TIMER_LO_EVENT
  0x88 TIMER_HI access not given — Trigger Timer HI of APB Timer with event
    [7:0] TIMER_HI_EVENT — Trigger and start APB Timer HI by the event with id that equals TIMER_HI_EVENT
0x109000 EventInterruptUnit group
  0x00 MASK_read access not given — This register contains the MASK (interrupt enable) for each of the 32 interrupts or events. Writing to 0x1A10_9004 sets the bits of the MASK register selected Writing to 0x1A10_9008 clears the bits of the MASK register selected.
    [31:0] MASK
  0x04 MASK_set access not given — This register contains the MASK (interrupt enable) for each of the 32 interrupts or events. Writing to 0x1A10_9004 sets the bits of the MASK register selected. Writing to 0x1A10_9008 clears the bits of the MASK register selected.
  0x08 MASK_clear access not given — This register contains the MASK (interrupt enable) for each of the 32 interrupts or events. Writing to 0x1A10_9004 sets the bits of the MASK register selected. Writing to 0x1A10_9008 clears the bits of the MASK register selected.
  0x0C INT_read access not given — This register contains the pending interrupts or events. Writing to 0x1A10_9010 sets the bits of the INT register selected. Writing to 0x1A10_9014 clears the bits of the INT register selected.
  0x10 INT_set access not given — INT_read
  0x14 INT_clear access not given
  0x18 ACK_read access not given — This register contains the ACK (interrupt enable) for each of the 32 interrupts or events. Writing to 0x1A10_901C sets the bits of the ACK register selected. Writing to 0x1A10_9020 clears the bits of the ACK register selected.
  0x1C ACK_set access not given — This register contains the ACK (interrupt enable) for each of the 32 interrupts or events. Writing to 0x1A10_901C sets the bits of the ACK register selected. Writing to 0x1A10_9020 clears the bits of the ACK register selected.
  0x20 ACK_clear access not given — This register contains the ACK (interrupt enable) for each of the 32 interrupts or events. Writing to 0x1A10_901C sets the bits of the ACK register selected. Writing to 0x1A10_9020 clears the bits of the ACK register selected.
  0x24 FIFO_DATA — Fifo Content. This is a read-only register that contain the first valid value of the FIFO.
    [31:0] FIFO_DATA — This is a read-only register that contain the first valid value of the FIFO
0x10B000 Timer group
  0x00 CFG_LO rw — Timer Low Configuration register
    [31] CASC — Timer low and Timer high 64-bit cascaded mode enable bit
    [15:8] PVAL — Timer low prescaler value. ftimer = fclk/(1 + P V AL)
    [7] CCFG — Timer low clock source configuration 0b0: FLL or FLL plus Prescaler 0b1: 32 kHz reference clock
    [6] PEN — Timer low prescaler enable bit
    [5] ONES — Timer low one shot configuration
    [4] MODE — Timer low continuous mode configuration 0b0: Continue incrementing timer low counter after a compare match with CMP_LO 0b1: Reset timer to after a compare match with CMP_LO
    [2] IRQEN — Timer low interrupt generation on compare match enable
    [1] RST — Timer low reset, cleared after the reset happened
    [0] EN — Timer enable (starts couting) bit
  0x04 CFG_HI rw — Timer High Configuration register
    [15:8] PVAL — Timer hi prescaler value. ftimer = fclk/(1 + PVAL)
    [7] CCFG — Timer hi clock source configuration 0b0: FLL or FLL plus Prescaler 0b1: 32 kHz reference clock
    [6] PEN — Timer hi prescaler enable bit
    [5] ONES — Timer hi one shot configuration
    [4] MODE — Timer hi continuous mode configuration 0b0: Continue incrementing timer hi counter after a compare match with CMP_HI 0b1: Reset timer to after a compare match with CMP_HI
    [2] IRQEN — Timer hi interrupt generation on compare match enable
    [1] RST — Timer high reset, cleared after the reset happened
    [0] EN — Timer enable (starts couting) bit
  0x08 CNT_LO rw — Timer Low counter value register
  0x0C CNT_HI rw — Timer High counter value register
  0x10 CMP_LO rw — Timer Low comparator value register
  0x14 CMP_HI rw — Timer High comparator value register
  0x18 START_LO rw — Start Timer Low counting register
    [0] START_LO — Timer high start command (sets EN in CFG_LO)
  0x1C START_HI rw — Start Timer High counting register
    [0] START_HI — Timer high reset command (writes RST in CFG_LO)
  0x20 RESET_LO rw — Reset Timer Low counter register
    [0] RESET_LO
  0x24 RESET_HI rw — Reset Timer High counter register
    [0] RESET_HI
0x120000 SDIO group
  0x20 CMD_OP wo
    [13:8] CMD_OPCODE
    [2:0] RSP_TYPE — Values for RSP_TYPE: 3'b000: RSP_TYPE_NULL 3'b001: RSP_TYPE_48_CRC 3'b010: RSP_TYPE_48_NOCRC 3'b011: RSP_TYPE_136 3'b100: RSP_TYPE_48_BSY
      0=RSP_TYPE_NULL; 1=RSP_TYPE_48_CRC; 2=RSP_TYPE_48_NOCRC; 3=RSP_TYPE_136; 4=RSP_TYPE_48_BSY
  0x24 CMD_ARG wo
    [31:0] CMD_ARGUMENT
  0x28 DATA_SETUP wo
    [25:16] BLOCK_SIZE, [15:8] Block_Num, [7:2] QUAD, [1] RWN, [0] EN
  0x2C START wo
    [0] START
  {0x30+4j} RSP{j} (j=0..3)
    [31:0] RESPONSE_WORD{j}
  0x40 CLK_DIV_0 rw
    [8] Valid, [7:0] Div_count
  0x44 STATUS rw reset 0x10 (reset mask 0x0)
    [31:16] Status
    [15:12] VHS — Note: Is reset value correct?
    [11:2] CARD_ERR
    [1] ERR
    [0] EOT
  0x48 CID0 — Card Identification Word0
    [31:0] card_id_word0
  {0x48+4j} CID{j} (j=1..3) — Card Identification Word {j}
    [31:0] card_id_word{j}
  0x58 RCA
    [15:0] RCA
